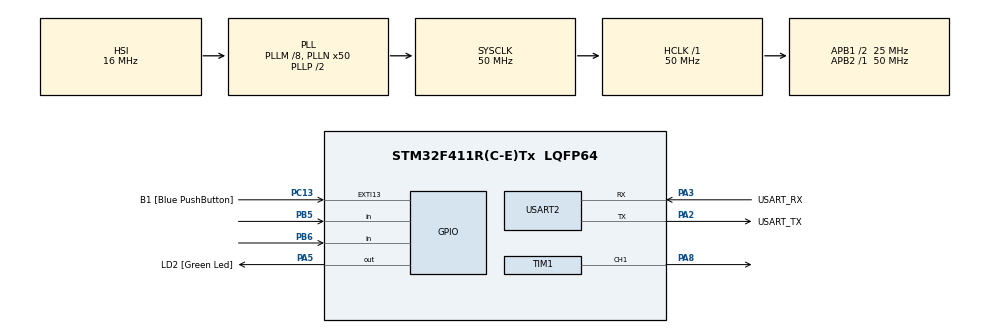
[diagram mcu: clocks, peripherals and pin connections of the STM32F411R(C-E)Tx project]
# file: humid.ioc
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FREERTOS.Tasks01=defaultTask,24,128,StartDefaultTask,Default,NULL,Dynamic,NULL,NULL;myTask02,24,128,StartTask02,Default,NULL,Dynamic,NULL,NULL;myTask03,24,128,StartTask03,Default,NULL,Dynamic,NULL,NULL
Mcu.Family=STM32F4
Mcu.Name=STM32F411R(C-E)Tx
Mcu.Package=LQFP64
NVIC.PriorityGroup=NVIC_PRIORITYGROUP_4
PA13.GPIO_Label=TMS
PA13.Mode=Serial_Wire
PA13.Signal=SYS_JTMS-SWDIO
PA14.GPIO_Label=TCK
PA14.Mode=Serial_Wire
PA14.Signal=SYS_JTCK-SWCLK
PA2.GPIO_Label=USART_TX
PA2.Mode=Asynchronous
PA2.Signal=USART2_TX
PA3.GPIO_Label=USART_RX
PA3.Mode=Asynchronous
PA3.Signal=USART2_RX
PA5.GPIO_Label=LD2 [Green Led]
PA5.Signal=GPIO_Output
PA8.Signal=S_TIM1_CH1
PB3.GPIO_Label=SWO
PB3.Signal=SYS_JTDO-SWO
PB5.GPIO_PuPd=GPIO_PULLDOWN
PB5.Signal=GPIO_Input
PB6.Signal=GPIO_Input
PC13-ANTI_TAMP.GPIO_Label=B1 [Blue PushButton]
PC13-ANTI_TAMP.GPIO_ModeDefaultEXTI=GPIO_MODE_IT_FALLING
PC13-ANTI_TAMP.Signal=GPXTI13
PC14-OSC32_IN.Mode=LSE-External-Oscillator
PC14-OSC32_IN.Signal=RCC_OSC32_IN
PC15-OSC32_OUT.Mode=LSE-External-Oscillator
PC15-OSC32_OUT.Signal=RCC_OSC32_OUT
PH0\ -\ OSC_IN.Mode=HSE-External-Oscillator
PH0\ -\ OSC_IN.Signal=RCC_OSC_IN
PH1\ -\ OSC_OUT.Mode=HSE-External-Oscillator
PH1\ -\ OSC_OUT.Signal=RCC_OSC_OUT
ProjectManager.HeapSize=0x200
ProjectManager.StackSize=0x400
ProjectManager.TargetToolchain=STM32CubeIDE
RCC.48MHZClocksFreq_Value=25000000
RCC.AHBFreq_Value=50000000
RCC.APB1CLKDivider=RCC_HCLK_DIV2
RCC.APB1Freq_Value=25000000
RCC.APB1TimFreq_Value=50000000
RCC.APB2Freq_Value=50000000
RCC.APB2TimFreq_Value=50000000
RCC.CortexFreq_Value=50000000
RCC.FLatency-AdvancedSettings=FLASH_LATENCY_1
RCC.HCLKFreq_Value=50000000
RCC.HSE_VALUE=8000000
RCC.HSI_VALUE=16000000
RCC.PLLM=8
RCC.PLLN=50
RCC.SYSCLKFreq_VALUE=50000000
RCC.SYSCLKSource=RCC_SYSCLKSOURCE_PLLCLK
RCC.VCOOutputFreq_Value=100000000
SH.S_TIM1_CH1.0=TIM1_CH1,PWM Generation1 CH1
TIM1.Channel-PWM\ Generation1\ CH1=TIM_CHANNEL_1
TIM1.Period=99
TIM1.Prescaler=49
USART2.VirtualMode=VM_ASYNC
VP_FREERTOS_VS_CMSIS_V2.Mode=CMSIS_V2
VP_TIM1_VS_ClockSourceINT.Mode=Internal
VP_TIM3_VS_ClockSourceINT.Mode=Internal
board=NUCLEO-F411RE

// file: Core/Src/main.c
/* USER CODE BEGIN Header */
/**
  ******************************************************************************
  * @file           : main.c
  * @brief          : Main program body
  ******************************************************************************
  * @attention
  *
  * Copyright (c) 2023 STMicroelectronics.
  * All rights reserved.
  *
  * This software is licensed under terms that can be found in the LICENSE file
  * in the root directory of this software component.
  * If no LICENSE file comes with this software, it is provided AS-IS.
  *
  ******************************************************************************
  */
/* USER CODE END Header */
#include "main.h"
#include "cmsis_os.h"

/* USER CODE BEGIN PD */
#define DHT22_PORT GPIOB
#define DHT22_PIN GPIO_PIN_8
/* USER CODE END PD */

TIM_HandleTypeDef htim1;
TIM_HandleTypeDef htim3;

UART_HandleTypeDef huart2;

/* Definitions for defaultTask */
osThreadId_t defaultTaskHandle;
const osThreadAttr_t defaultTask_attributes = {
  .name = "defaultTask",
  .stack_size = 128 * 4,
  .priority = (osPriority_t) osPriorityNormal,
};
/* Definitions for myTask02 */
osThreadId_t myTask02Handle;
const osThreadAttr_t myTask02_attributes = {
  .name = "myTask02",
  .stack_size = 128 * 4,
  .priority = (osPriority_t) osPriorityNormal,
};
/* Definitions for myTask03 */
osThreadId_t myTask03Handle;
const osThreadAttr_t myTask03_attributes = {
  .name = "myTask03",
  .stack_size = 128 * 4,
  .priority = (osPriority_t) osPriorityNormal,
};

void SystemClock_Config(void);
static void MX_GPIO_Init(void);
static void MX_USART2_UART_Init(void);
static void MX_TIM3_Init(void);
static void MX_TIM1_Init(void);
void StartDefaultTask(void *argument);
void StartTask02(void *argument);
void StartTask03(void *argument);

/* USER CODE BEGIN 0 */
void delay(uint16_t Delay){ // will delay = Delay * 1 micro second (Delay should not exceed 2^16 - 1)
    __HAL_TIM_SET_COUNTER(&htim3,0);  // set the counter value a 0
    while ((uint16_t)__HAL_TIM_GET_COUNTER(&htim3) < Delay);// wait for the counter to reach the us input in the parameter
}

uint8_t Rh_byte1, Rh_byte2, Temp_byte1, Temp_byte2, SUM;
uint16_t RH, TEMP;

float Temp = 0,Humi = 0;
uint8_t Presence = 0;

void Set_Pin_Output (GPIO_TypeDef *GPIOx, uint16_t GPIO_Pin){
	GPIO_InitTypeDef GPIO_InitStruct = {0};
	GPIO_InitStruct.Pin = GPIO_Pin;
	GPIO_InitStruct.Mode = GPIO_MODE_OUTPUT_PP;
	GPIO_InitStruct.Speed = GPIO_SPEED_FREQ_LOW;
	HAL_GPIO_Init(GPIOx, &GPIO_InitStruct);
}

void Set_Pin_Input (GPIO_TypeDef *GPIOx, uint16_t GPIO_Pin){
	GPIO_InitTypeDef GPIO_InitStruct = {0};
	GPIO_InitStruct.Pin = GPIO_Pin;
	GPIO_InitStruct.Mode = GPIO_MODE_INPUT;
	GPIO_InitStruct.Pull = GPIO_PULLUP;
	HAL_GPIO_Init(GPIOx, &GPIO_InitStruct);
}

void DHT22_Start (void)
{
	Set_Pin_Output(DHT22_PORT, DHT22_PIN); // set the pin as output
	HAL_GPIO_WritePin (DHT22_PORT, DHT22_PIN, 0);   // pull the pin low
	HAL_Delay(18);   // wait for > 1ms

	HAL_GPIO_WritePin (DHT22_PORT, DHT22_PIN, 1);   // pull the pin high
	delay (20);   // wait for 30us
	HAL_GPIO_WritePin (DHT22_PORT, DHT22_PIN, 0);   // pull the pin high

	Set_Pin_Input(DHT22_PORT, DHT22_PIN);   // set as input
}
uint8_t DHT22_Check_Response (void)
{
	Set_Pin_Input(DHT22_PORT, DHT22_PIN);   // set as input
	uint8_t Response = 0;
	delay (40);  // wait for 40us
	if (!(HAL_GPIO_ReadPin (DHT22_PORT, DHT22_PIN))) // if the pin is low
	{
		delay (80);   // wait for 80us

		if ((HAL_GPIO_ReadPin (DHT22_PORT, DHT22_PIN))) Response = 1;  // if the pin is high, response is ok
		else Response = -1;
	}

	while ((HAL_GPIO_ReadPin (DHT22_PORT, DHT22_PIN)));// wait for the pin to go low
	return Response;
}
uint8_t DHT22_Read (void)
{
	uint8_t i=0,j;
	for (j=0;j<8;j++)
	{
		while (!(HAL_GPIO_ReadPin (DHT22_PORT, DHT22_PIN))){
			delay(1); // wait for the pin to go high
		}
		delay (40);   // wait for 40 us
		//HAL_GPIO_TogglePin(GPIOC, GPIO_PIN_9);
		if (!(HAL_GPIO_ReadPin (DHT22_PORT, DHT22_PIN)))   // if the pin is low
		{
			i&= ~(1<<(7-j));   // write 0
		}
		else i|= (1<<(7-j));  // if the pin is high, write 1
		while ((HAL_GPIO_ReadPin (DHT22_PORT, DHT22_PIN))){
			delay(1);  // wait for the pin to go low
		}
	}

	return i;
}

/* USER CODE END 0 */

int main(void)
{

  /* MCU Configuration--------------------------------------------------------*/

  /* Reset of all peripherals, Initializes the Flash interface and the Systick. */
  HAL_Init();

  /* Configure the system clock */
  SystemClock_Config();

  /* Initialize all configured peripherals */
  MX_GPIO_Init();
  MX_USART2_UART_Init();
  MX_TIM3_Init();
  MX_TIM1_Init();
  /* USER CODE BEGIN 2 */

  //HAL_TIM_Base_Start(&htim3);
  //uint8_t T[3],H[3],Check;
  //uint16_t Tsum;

  /* USER CODE END 2 */

  /* Init scheduler */
  osKernelInitialize();

  /* Create the thread(s) */
  /* creation of defaultTask */
  defaultTaskHandle = osThreadNew(StartDefaultTask, NULL, &defaultTask_attributes);

  /* creation of myTask02 */
  myTask02Handle = osThreadNew(StartTask02, NULL, &myTask02_attributes);

  /* creation of myTask03 */
  myTask03Handle = osThreadNew(StartTask03, NULL, &myTask03_attributes);

  /* Start scheduler */
  osKernelStart();
  /* We should never get here as control is now taken by the scheduler */
  /* Infinite loop */
  while (1)
  {
	  	  /*HAL_UART_Transmit(&huart2, "Do\r\n", 4, 10);
	  	  DHT22_Start();
	  	  Presence = DHT22_Check_Response();
	  	  Rh_byte1 = DHT22_Read();
	  	  Rh_byte2 = DHT22_Read();
	  	  Temp_byte1 = DHT22_Read();
	  	  Temp_byte2 = DHT22_Read();
	  	  SUM = DHT22_Read();
	  	  Check = Rh_byte1 + Rh_byte2 + Temp_byte1 + Temp_byte2;
	  	  /*
	  	  TEMP = ((Temp_byte1<<8)|Temp_byte2)&32767;
	  	  RH = ((Rh_byte1<<8)|Rh_byte2)&32767;
	  	  */
	  	  Temp = (float)(TEMP/10.0);
	  	  Humi = (float)(RH/10.0);

	  	  Tsum = Temp_byte1*256 + Temp_byte2;
	  	  T[0] = '0' + Tsum/100;
	  	  T[1] = '0' + (Tsum%100)/10;
	  	  T[2] = '0' + (Tsum%10);
	  //	  H[0] = '0' + Temp_byte2/100;
	  //	  H[1] = '0' + (Temp_byte2%100)/10;
	  //	  H[2] = '0' + (Temp_byte2%10);
	  	  HAL_UART_Transmit(&huart2, T, 3, 10);
	  	  HAL_UART_Transmit(&huart2, "\r\n", 2, 10);
	  //	  HAL_UART_Transmit(&huart2, H, 3, 10);
	  //	  HAL_UART_Transmit(&huart2, "\r\n", 2, 10);
	  	  if(Check == SUM){
	  		  HAL_UART_Transmit(&huart2, "Good\r\n", 6, 10);
	  	  }else{
	  		  HAL_UART_Transmit(&huart2, "Bad\r\n", 5, 10);
	  	  }
	  	  HAL_Delay(3000);*/
  }
}

void SystemClock_Config(void)
{
  RCC_OscInitTypeDef RCC_OscInitStruct = {0};
  RCC_ClkInitTypeDef RCC_ClkInitStruct = {0};

  /** Configure the main internal regulator output voltage
  */
  __HAL_RCC_PWR_CLK_ENABLE();
  __HAL_PWR_VOLTAGESCALING_CONFIG(PWR_REGULATOR_VOLTAGE_SCALE1);

  /** Initializes the RCC Oscillators according to the specified parameters
  * in the RCC_OscInitTypeDef structure.
  */
  RCC_OscInitStruct.OscillatorType = RCC_OSCILLATORTYPE_HSI;
  RCC_OscInitStruct.HSIState = RCC_HSI_ON;
  RCC_OscInitStruct.HSICalibrationValue = RCC_HSICALIBRATION_DEFAULT;
  RCC_OscInitStruct.PLL.PLLState = RCC_PLL_ON;
  RCC_OscInitStruct.PLL.PLLSource = RCC_PLLSOURCE_HSI;
  RCC_OscInitStruct.PLL.PLLM = 8;
  RCC_OscInitStruct.PLL.PLLN = 50;
  RCC_OscInitStruct.PLL.PLLP = RCC_PLLP_DIV2;
  RCC_OscInitStruct.PLL.PLLQ = 4;
  if (HAL_RCC_OscConfig(&RCC_OscInitStruct) != HAL_OK)
  {
    Error_Handler();
  }

  /** Initializes the CPU, AHB and APB buses clocks
  */
  RCC_ClkInitStruct.ClockType = RCC_CLOCKTYPE_HCLK|RCC_CLOCKTYPE_SYSCLK
                              |RCC_CLOCKTYPE_PCLK1|RCC_CLOCKTYPE_PCLK2;
  RCC_ClkInitStruct.SYSCLKSource = RCC_SYSCLKSOURCE_PLLCLK;
  RCC_ClkInitStruct.AHBCLKDivider = RCC_SYSCLK_DIV1;
  RCC_ClkInitStruct.APB1CLKDivider = RCC_HCLK_DIV2;
  RCC_ClkInitStruct.APB2CLKDivider = RCC_HCLK_DIV1;

  if (HAL_RCC_ClockConfig(&RCC_ClkInitStruct, FLASH_LATENCY_1) != HAL_OK)
  {
    Error_Handler();
  }
}

static void MX_TIM1_Init(void)
{

  TIM_ClockConfigTypeDef sClockSourceConfig = {0};
  TIM_MasterConfigTypeDef sMasterConfig = {0};
  TIM_OC_InitTypeDef sConfigOC = {0};
  TIM_BreakDeadTimeConfigTypeDef sBreakDeadTimeConfig = {0};

  htim1.Instance = TIM1;
  htim1.Init.Prescaler = 49;
  htim1.Init.CounterMode = TIM_COUNTERMODE_UP;
  htim1.Init.Period = 99;
  htim1.Init.ClockDivision = TIM_CLOCKDIVISION_DIV1;
  htim1.Init.RepetitionCounter = 0;
  htim1.Init.AutoReloadPreload = TIM_AUTORELOAD_PRELOAD_DISABLE;
  if (HAL_TIM_Base_Init(&htim1) != HAL_OK)
  {
    Error_Handler();
  }
  sClockSourceConfig.ClockSource = TIM_CLOCKSOURCE_INTERNAL;
  if (HAL_TIM_ConfigClockSource(&htim1, &sClockSourceConfig) != HAL_OK)
  {
    Error_Handler();
  }
  if (HAL_TIM_PWM_Init(&htim1) != HAL_OK)
  {
    Error_Handler();
  }
  sMasterConfig.MasterOutputTrigger = TIM_TRGO_RESET;
  sMasterConfig.MasterSlaveMode = TIM_MASTERSLAVEMODE_DISABLE;
  if (HAL_TIMEx_MasterConfigSynchronization(&htim1, &sMasterConfig) != HAL_OK)
  {
    Error_Handler();
  }
  sConfigOC.OCMode = TIM_OCMODE_PWM1;
  sConfigOC.Pulse = 0;
  sConfigOC.OCPolarity = TIM_OCPOLARITY_HIGH;
  sConfigOC.OCNPolarity = TIM_OCNPOLARITY_HIGH;
  sConfigOC.OCFastMode = TIM_OCFAST_DISABLE;
  sConfigOC.OCIdleState = TIM_OCIDLESTATE_RESET;
  sConfigOC.OCNIdleState = TIM_OCNIDLESTATE_RESET;
  if (HAL_TIM_PWM_ConfigChannel(&htim1, &sConfigOC, TIM_CHANNEL_1) != HAL_OK)
  {
    Error_Handler();
  }
  sBreakDeadTimeConfig.OffStateRunMode = TIM_OSSR_DISABLE;
  sBreakDeadTimeConfig.OffStateIDLEMode = TIM_OSSI_DISABLE;
  sBreakDeadTimeConfig.LockLevel = TIM_LOCKLEVEL_OFF;
  sBreakDeadTimeConfig.DeadTime = 0;
  sBreakDeadTimeConfig.BreakState = TIM_BREAK_DISABLE;
  sBreakDeadTimeConfig.BreakPolarity = TIM_BREAKPOLARITY_HIGH;
  sBreakDeadTimeConfig.AutomaticOutput = TIM_AUTOMATICOUTPUT_DISABLE;
  if (HAL_TIMEx_ConfigBreakDeadTime(&htim1, &sBreakDeadTimeConfig) != HAL_OK)
  {
    Error_Handler();
  }
  HAL_TIM_MspPostInit(&htim1);

}

static void MX_TIM3_Init(void)
{

  TIM_ClockConfigTypeDef sClockSourceConfig = {0};
  TIM_MasterConfigTypeDef sMasterConfig = {0};

  htim3.Instance = TIM3;
  htim3.Init.Prescaler = 49;
  htim3.Init.CounterMode = TIM_COUNTERMODE_UP;
  htim3.Init.Period = 99;
  htim3.Init.ClockDivision = TIM_CLOCKDIVISION_DIV1;
  htim3.Init.AutoReloadPreload = TIM_AUTORELOAD_PRELOAD_DISABLE;
  if (HAL_TIM_Base_Init(&htim3) != HAL_OK)
  {
    Error_Handler();
  }
  sClockSourceConfig.ClockSource = TIM_CLOCKSOURCE_INTERNAL;
  if (HAL_TIM_ConfigClockSource(&htim3, &sClockSourceConfig) != HAL_OK)
  {
    Error_Handler();
  }
  sMasterConfig.MasterOutputTrigger = TIM_TRGO_RESET;
  sMasterConfig.MasterSlaveMode = TIM_MASTERSLAVEMODE_DISABLE;
  if (HAL_TIMEx_MasterConfigSynchronization(&htim3, &sMasterConfig) != HAL_OK)
  {
    Error_Handler();
  }

}

static void MX_USART2_UART_Init(void)
{

  huart2.Instance = USART2;
  huart2.Init.BaudRate = 115200;
  huart2.Init.WordLength = UART_WORDLENGTH_8B;
  huart2.Init.StopBits = UART_STOPBITS_1;
  huart2.Init.Parity = UART_PARITY_NONE;
  huart2.Init.Mode = UART_MODE_TX_RX;
  huart2.Init.HwFlowCtl = UART_HWCONTROL_NONE;
  huart2.Init.OverSampling = UART_OVERSAMPLING_16;
  if (HAL_UART_Init(&huart2) != HAL_OK)
  {
    Error_Handler();
  }

}

static void MX_GPIO_Init(void)
{
  GPIO_InitTypeDef GPIO_InitStruct = {0};

  /* GPIO Ports Clock Enable */
  __HAL_RCC_GPIOC_CLK_ENABLE();
  __HAL_RCC_GPIOH_CLK_ENABLE();
  __HAL_RCC_GPIOA_CLK_ENABLE();
  __HAL_RCC_GPIOB_CLK_ENABLE();

  /*Configure GPIO pin Output Level */
  HAL_GPIO_WritePin(LD2_GPIO_Port, LD2_Pin, GPIO_PIN_RESET);

  /*Configure GPIO pin Output Level */
  HAL_GPIO_WritePin(GPIOB, GPIO_PIN_8, GPIO_PIN_RESET);

  /*Configure GPIO pin : B1_Pin */
  GPIO_InitStruct.Pin = B1_Pin;
  GPIO_InitStruct.Mode = GPIO_MODE_IT_FALLING;
  GPIO_InitStruct.Pull = GPIO_NOPULL;
  HAL_GPIO_Init(B1_GPIO_Port, &GPIO_InitStruct);

  /*Configure GPIO pin : LD2_Pin */
  GPIO_InitStruct.Pin = LD2_Pin;
  GPIO_InitStruct.Mode = GPIO_MODE_OUTPUT_PP;
  GPIO_InitStruct.Pull = GPIO_NOPULL;
  GPIO_InitStruct.Speed = GPIO_SPEED_FREQ_LOW;
  HAL_GPIO_Init(LD2_GPIO_Port, &GPIO_InitStruct);

  /*Configure GPIO pin : PB5 */
  GPIO_InitStruct.Pin = GPIO_PIN_5;
  GPIO_InitStruct.Mode = GPIO_MODE_INPUT;
  GPIO_InitStruct.Pull = GPIO_PULLDOWN;
  HAL_GPIO_Init(GPIOB, &GPIO_InitStruct);

  /*Configure GPIO pin : PB6 */
  GPIO_InitStruct.Pin = GPIO_PIN_6;
  GPIO_InitStruct.Mode = GPIO_MODE_INPUT;
  GPIO_InitStruct.Pull = GPIO_NOPULL;
  HAL_GPIO_Init(GPIOB, &GPIO_InitStruct);

  /*Configure GPIO pin : PB8 */
  GPIO_InitStruct.Pin = GPIO_PIN_8;
  GPIO_InitStruct.Mode = GPIO_MODE_OUTPUT_PP;
  GPIO_InitStruct.Pull = GPIO_NOPULL;
  GPIO_InitStruct.Speed = GPIO_SPEED_FREQ_LOW;
  HAL_GPIO_Init(GPIOB, &GPIO_InitStruct);

}

/* USER CODE BEGIN Header_StartDefaultTask */
/**
  * @brief  Function implementing the defaultTask thread.
  * @param  argument: Not used
  * @retval None
  */
/*
HAL_TIM_Base_Start(&htim3);
uint8_t T[3],H[3],Check;
uint16_t Tsum;
*/
/* USER CODE END Header_StartDefaultTask */
void StartDefaultTask(void *argument)
{
  /* USER CODE BEGIN 5 */
	/*HAL_TIM_Base_Start(&htim3);
	uint8_t T[3],H[3],Check;
	uint16_t Tsum;*/
  /* Infinite loop */
  for(;;)
  {
	  	  HAL_UART_Transmit(&huart2, "Do\r\n", 4, 10);
	  	  DHT22_Start();
	  	  Presence = DHT22_Check_Response();
	  	  Rh_byte1 = DHT22_Read();
	  	  Rh_byte2 = DHT22_Read();
	  	  Temp_byte1 = DHT22_Read();
	  	  Temp_byte2 = DHT22_Read();
	  	  SUM = DHT22_Read();
	  	  Check = Rh_byte1 + Rh_byte2 + Temp_byte1 + Temp_byte2;

	  	  //TEMP = ((Temp_byte1<<8)|Temp_byte2)&32767;
	  	 // RH = ((Rh_byte1<<8)|Rh_byte2)&32767;

	  	  Temp = (float)(TEMP/10.0);
	  	  Humi = (float)(RH/10.0);

	  	  Tsum = Temp_byte1*256 + Temp_byte2;
	  	  T[0] = '0' + Tsum/100;
	  	  T[1] = '0' + (Tsum%100)/10;
	  	  T[2] = '0' + (Tsum%10);
	  //	  H[0] = '0' + Temp_byte2/100;
	  //	  H[1] = '0' + (Temp_byte2%100)/10;
	  //	  H[2] = '0' + (Temp_byte2%10);
	  	  HAL_UART_Transmit(&huart2, T, 3, 10);
	  	  HAL_UART_Transmit(&huart2, "\r\n", 2, 10);
	  //	  HAL_UART_Transmit(&huart2, H, 3, 10);
	  //	  HAL_UART_Transmit(&huart2, "\r\n", 2, 10);
	  	  if(Check == SUM){
	  		  HAL_UART_Transmit(&huart2, "Good\r\n", 6, 10);
	  	  }else{
	  		  HAL_UART_Transmit(&huart2, "Bad\r\n", 5, 10);
	  	  }
	  	  osDelay(3000);

    //osDelay(1);
  }
  /* USER CODE END 5 */
}

void StartTask02(void *argument)
{
  /* USER CODE BEGIN StartTask02 */
  /* Infinite loop */

	  	    //pwm for trig
	  	    int hit = 0;
	  	    int miss_count = 0;
	  	    uint8_t state = 0;
	  	    int delay;
	  	    int echo=1;

	  	    HAL_TIM_PWM_Start(&htim1, TIM_CHANNEL_1);

	  	    TIM1->CCR1 = 20;

	  	    for (;;) {
	  	        uint8_t test = "TEST\r\n";
	  	        //HAL_UART_Transmit(&huart1, &test, sizeof(test), HAL_MAX_DELAY);
	  	        delay = 1000001;
	  	        echo =  HAL_GPIO_ReadPin(GPIOB, GPIO_PIN_6);
	  	        // HAL_GPIO_WritePin(GPIOA, GPIO_PIN_5, echo);

	  	        if (echo) {
	  	            delay = 0;
	  	            while ( HAL_GPIO_ReadPin(GPIOB, GPIO_PIN_6)) {
	  	                delay++;
	  	            }
	  	        }

	  	        if (delay < 1000001) {

	  	            if (delay < 1000) {
	  	                hit++;
	  	                miss_count = 0;
	  	            }
	  	            else {
	  	                if (miss_count++ > 100) {
	  	                    hit = 0;
	  	                }
	  	             }

	  	            if (hit > 100) {
	  	                if (state == 0) {
	  	                    //HAL_GPIO_WritePin(GPIOA, GPIO_PIN_5, 1);

	  	                    state = 1;
	  	                }
	  	            } else {
	  	                if (state == 1) {
	  	                    //HAL_GPIO_WritePin(GPIOA, GPIO_PIN_5, 0);

	  	                    state = 0;
	  	                }
	  	            }

	  	            uint8_t pData[7] = {' ',' ',' ',' ',' ',' ',' '};
	  	            //sprintf(pData, "%d\r\n", delay);
	  	            //HAL_UART_Transmit(&huart2, &pData, 7, HAL_MAX_DELAY);
	  	            osDelay(10);
	  	        }
	  	    }
	  	  //osDelay(10);

	 //osDelay(1);
  /* USER CODE END StartTask02 */
}

void StartTask03(void *argument)
{
  /* USER CODE BEGIN StartTask03 */
	  for(;;)
	  {
		  uint8_t sensorState = HAL_GPIO_ReadPin(GPIOB, GPIO_PIN_5);
		  HAL_GPIO_WritePin(GPIOA, GPIO_PIN_5,sensorState);

	  }
   osDelay(1);
  /* USER CODE END StartTask03 */
}

void Error_Handler(void)
{
  __disable_irq();
  while (1)
  {
  }
}
